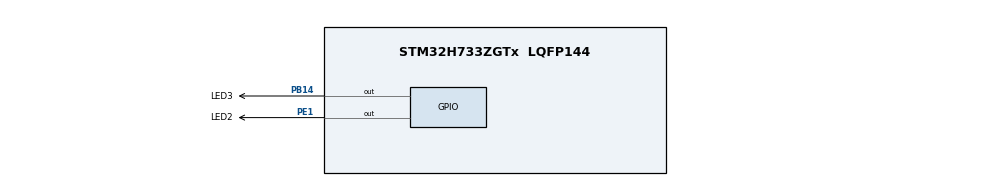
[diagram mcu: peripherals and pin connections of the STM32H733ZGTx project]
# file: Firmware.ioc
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FREERTOS.Tasks01=defaultTask,24,128,StartDefaultTask,Default,NULL,Dynamic,NULL,NULL
FREERTOS.configENABLE_FPU=1
FREERTOS.configTOTAL_HEAP_SIZE=16000
Mcu.Family=STM32H7
Mcu.Name=STM32H733ZGTx
Mcu.Package=LQFP144
NVIC.PriorityGroup=NVIC_PRIORITYGROUP_4
NVIC.TIM1_UP_IRQn=true\:15\:0\:false\:false\:true\:false\:false\:true\:true
NVIC.TimeBase=TIM1_UP_IRQn
NVIC.TimeBaseIP=TIM1
PB14.GPIO_Label=LED3
PB14.Signal=GPIO_Output
PC14-OSC32_IN.Mode=LSE-External-Oscillator
PC14-OSC32_IN.Signal=RCC_OSC32_IN
PC15-OSC32_OUT.Mode=LSE-External-Oscillator
PC15-OSC32_OUT.Signal=RCC_OSC32_OUT
PE1.GPIO_Label=LED2
PE1.Signal=GPIO_Output
PH0-OSC_IN.Mode=HSE-External-Oscillator
PH0-OSC_IN.Signal=RCC_OSC_IN
PH1-OSC_OUT.Mode=HSE-External-Oscillator
PH1-OSC_OUT.Signal=RCC_OSC_OUT
ProjectManager.HeapSize=0x200
ProjectManager.StackSize=0x400
ProjectManager.TargetToolchain=Makefile
RCC.ADCFreq_Value=50390625
RCC.APB1Freq_Value=101562500
RCC.APB2Freq_Value=101562500
RCC.APB3Freq_Value=101562500
RCC.APB4Freq_Value=101562500
RCC.CortexFreq_Value=406250000
RCC.D1PPRE=RCC_APB3_DIV2
RCC.D2PPRE1=RCC_APB1_DIV2
RCC.D2PPRE2=RCC_APB2_DIV2
RCC.D3PPRE=RCC_APB4_DIV2
RCC.DIVM1=4
RCC.DIVN1=130
RCC.HCLKFreq_Value=203125000
RCC.HPRE=RCC_HCLK_DIV2
RCC.HSE_VALUE=25000000
RCC.PLLSourceVirtual=RCC_PLLSOURCE_HSE
RCC.SYSCLKFreq_VALUE=406250000
RCC.SYSCLKSource=RCC_SYSCLKSOURCE_PLLCLK
RCC.USBFreq_Value=406250000
VP_FREERTOS_VS_CMSIS_V2.Mode=CMSIS_V2
VP_SYS_VS_tim1.Mode=TIM1
board=custom

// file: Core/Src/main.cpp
/* USER CODE BEGIN Header */
/**
  ******************************************************************************
  * @file           : main.c
  * @brief          : Main program body
  ******************************************************************************
  * @attention
  *
  * Copyright (c) 2023 STMicroelectronics.
  * All rights reserved.
  *
  * This software is licensed under terms that can be found in the LICENSE file
  * in the root directory of this software component.
  * If no LICENSE file comes with this software, it is provided AS-IS.
  *
  ******************************************************************************
  */
/* USER CODE END Header */
#include "main.h"
#include "cmsis_os.h"

/* USER CODE BEGIN Includes */
#include "LED.h"
/* USER CODE END Includes */

/* Definitions for defaultTask */
osThreadId_t defaultTaskHandle;
const osThreadAttr_t defaultTask_attributes = {
  .name = "defaultTask",
  .stack_size = 128 * 4,
  .priority = (osPriority_t) osPriorityNormal,
};

void SystemClock_Config(void);
static void MX_GPIO_Init(void);
void StartDefaultTask(void *argument);

int main(void)
{
  /* USER CODE BEGIN 1 */
  STM32LED::LED2= new STM32LED::LED(GPIOE, GPIO_PIN_1);
  STM32LED::LED3= new STM32LED::LED(GPIOB, GPIO_PIN_14);
  /* USER CODE END 1 */

  /* MCU Configuration--------------------------------------------------------*/

  /* Reset of all peripherals, Initializes the Flash interface and the Systick. */
  HAL_Init();

  /* Configure the system clock */
  SystemClock_Config();

  /* Initialize all configured peripherals */
  MX_GPIO_Init();

  /* Init scheduler */
  osKernelInitialize();

  /* Create the thread(s) */
  /* creation of defaultTask */
  defaultTaskHandle = osThreadNew(StartDefaultTask, NULL, &defaultTask_attributes);

  /* Start scheduler */
  osKernelStart();
  /* We should never get here as control is now taken by the scheduler */
  /* Infinite loop */
  while (1)
  {

  }
}

void SystemClock_Config(void)
{
  RCC_OscInitTypeDef RCC_OscInitStruct = {0};
  RCC_ClkInitTypeDef RCC_ClkInitStruct = {0};

  /** Supply configuration update enable
  */
  HAL_PWREx_ConfigSupply(PWR_LDO_SUPPLY);

  /** Configure the main internal regulator output voltage
  */
  __HAL_PWR_VOLTAGESCALING_CONFIG(PWR_REGULATOR_VOLTAGE_SCALE0);

  while(!__HAL_PWR_GET_FLAG(PWR_FLAG_VOSRDY)) {}

  /** Initializes the RCC Oscillators according to the specified parameters
  * in the RCC_OscInitTypeDef structure.
  */
  RCC_OscInitStruct.OscillatorType = RCC_OSCILLATORTYPE_HSE;
  RCC_OscInitStruct.HSEState = RCC_HSE_ON;
  RCC_OscInitStruct.PLL.PLLState = RCC_PLL_ON;
  RCC_OscInitStruct.PLL.PLLSource = RCC_PLLSOURCE_HSE;
  RCC_OscInitStruct.PLL.PLLM = 4;
  RCC_OscInitStruct.PLL.PLLN = 130;
  RCC_OscInitStruct.PLL.PLLP = 2;
  RCC_OscInitStruct.PLL.PLLQ = 2;
  RCC_OscInitStruct.PLL.PLLR = 2;
  RCC_OscInitStruct.PLL.PLLRGE = RCC_PLL1VCIRANGE_2;
  RCC_OscInitStruct.PLL.PLLVCOSEL = RCC_PLL1VCOWIDE;
  RCC_OscInitStruct.PLL.PLLFRACN = 0;
  if (HAL_RCC_OscConfig(&RCC_OscInitStruct) != HAL_OK)
  {
    Error_Handler();
  }

  /** Initializes the CPU, AHB and APB buses clocks
  */
  RCC_ClkInitStruct.ClockType = RCC_CLOCKTYPE_HCLK|RCC_CLOCKTYPE_SYSCLK
                              |RCC_CLOCKTYPE_PCLK1|RCC_CLOCKTYPE_PCLK2
                              |RCC_CLOCKTYPE_D3PCLK1|RCC_CLOCKTYPE_D1PCLK1;
  RCC_ClkInitStruct.SYSCLKSource = RCC_SYSCLKSOURCE_PLLCLK;
  RCC_ClkInitStruct.SYSCLKDivider = RCC_SYSCLK_DIV1;
  RCC_ClkInitStruct.AHBCLKDivider = RCC_HCLK_DIV2;
  RCC_ClkInitStruct.APB3CLKDivider = RCC_APB3_DIV2;
  RCC_ClkInitStruct.APB1CLKDivider = RCC_APB1_DIV2;
  RCC_ClkInitStruct.APB2CLKDivider = RCC_APB2_DIV2;
  RCC_ClkInitStruct.APB4CLKDivider = RCC_APB4_DIV2;

  if (HAL_RCC_ClockConfig(&RCC_ClkInitStruct, FLASH_LATENCY_2) != HAL_OK)
  {
    Error_Handler();
  }
}

static void MX_GPIO_Init(void)
{
  GPIO_InitTypeDef GPIO_InitStruct = {0};

  /* GPIO Ports Clock Enable */
  __HAL_RCC_GPIOC_CLK_ENABLE();
  __HAL_RCC_GPIOH_CLK_ENABLE();
  __HAL_RCC_GPIOB_CLK_ENABLE();
  __HAL_RCC_GPIOE_CLK_ENABLE();

  /*Configure GPIO pin Output Level */
  HAL_GPIO_WritePin(LED3_GPIO_Port, LED3_Pin, GPIO_PIN_RESET);

  /*Configure GPIO pin Output Level */
  HAL_GPIO_WritePin(LED2_GPIO_Port, LED2_Pin, GPIO_PIN_RESET);

  /*Configure GPIO pin : LED3_Pin */
  GPIO_InitStruct.Pin = LED3_Pin;
  GPIO_InitStruct.Mode = GPIO_MODE_OUTPUT_PP;
  GPIO_InitStruct.Pull = GPIO_NOPULL;
  GPIO_InitStruct.Speed = GPIO_SPEED_FREQ_LOW;
  HAL_GPIO_Init(LED3_GPIO_Port, &GPIO_InitStruct);

  /*Configure GPIO pin : LED2_Pin */
  GPIO_InitStruct.Pin = LED2_Pin;
  GPIO_InitStruct.Mode = GPIO_MODE_OUTPUT_PP;
  GPIO_InitStruct.Pull = GPIO_NOPULL;
  GPIO_InitStruct.Speed = GPIO_SPEED_FREQ_LOW;
  HAL_GPIO_Init(LED2_GPIO_Port, &GPIO_InitStruct);

}

void StartDefaultTask(void *argument)
{
  /* USER CODE BEGIN 5 */
  /* Infinite loop */
  for(;;)
  {
    STM32LED:: LED2 -> toggle();
    osDelay(200);
    STM32LED:: LED3 -> toggle();
    osDelay(200);
  }
  /* USER CODE END 5 */
}

void HAL_TIM_PeriodElapsedCallback(TIM_HandleTypeDef *htim)
{
  if (htim->Instance == TIM1) {
    HAL_IncTick();
  }
}

void Error_Handler(void)
{
  __disable_irq();
  while (1)
  {
  }
}
